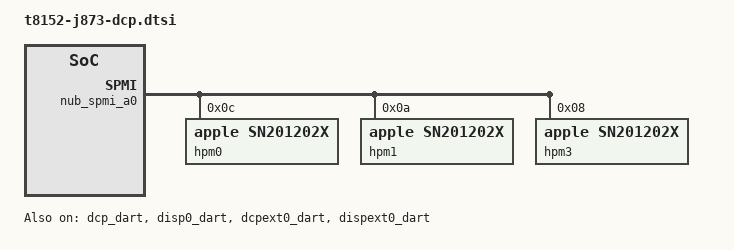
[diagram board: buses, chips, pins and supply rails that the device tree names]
// SPDX-License-Identifier: GPL-2.0+ OR MIT
/*
 * J873g displays: the rear USB-C ports and the HDMI port, driven through
 * the DCP firmware's iBoot interface (apple,t8152-dcp-iboot). The
 * bootloader trains the displays and hands both DCPs over with their RTKit
 * sessions running.
 *
 * Resources are from the 26A434 ADT: dcp (iop,ascwrap-v8, post-office
 * mailbox 5 with alias: 0x316020000 + 2 * 5 * 0x80), dart-dcp (SID 23),
 * dart-disp0 (scanout SID 0), and the atc-phyN PHY windows. The Gen3
 * display DARTs stay locked by iBoot, each with its own live root, so the
 * scanout stream is a child device with its own domain. Linux tables are
 * published into vacant root slots, so the DMA window is the upper half of
 * the 64 GiB vm-base window, above the firmware's and the bootloader's
 * mappings.
 */
#include <dt-bindings/gpio/gpio.h>
#include <dt-bindings/spmi/spmi.h>

&dcp_dart {
	apple,dma-range = <0x108 0x0 0x8 0x0>;
	status = "okay";
};

&disp0_dart {
	apple,dma-range = <0x108 0x0 0x8 0x0>;
	status = "okay";
};

&dcpext0_dart {
	apple,dma-range = <0x108 0x0 0x8 0x0>;
	status = "okay";
};

&dispext0_dart {
	apple,dma-range = <0x108 0x0 0x8 0x0>;
	status = "okay";
};

/ {
	soc {
		/*
		 * ADT /arm-io/nub-spmi-a0 (gen 4): the USB-C PD controllers of
		 * the three rear ports, each of which can carry the USB-C display.
		 */
		nub_spmi_a0: spmi@308908000 {
			compatible = "apple,t8152-spmi", "apple,t8142-spmi";
			reg = <0x3 0x08908000 0x0 0x4000>;
			#address-cells = <2>;
			#size-cells = <0>;

			/* back-middle */
			hpm0: usb-pd@c {
				compatible = "apple,sn201202x";
				reg = <0xc SPMI_USID>;
			};

			/* back-left */
			hpm1: usb-pd@a {
				compatible = "apple,sn201202x";
				reg = <0xa SPMI_USID>;
			};

			/* back-right */
			hpm3: usb-pd@8 {
				compatible = "apple,sn201202x";
				reg = <0x8 SPMI_USID>;
			};
		};

		/*
		 * ADT aop-gpio. Its interrupts are the AOP's, so it has no
		 * interrupt controller here; the HDMI HPD line is polled.
		 */
		pinctrl_aop: pinctrl@310824000 {
			compatible = "apple,t8152-pinctrl", "apple,t8103-pinctrl";
			reg = <0x3 0x10824000 0x0 0x4000>;
			gpio-controller;
			#gpio-cells = <2>;
			gpio-ranges = <&pinctrl_aop 0 0 77>;
			apple,npins = <77>;
		};

		dcp_mbox: mailbox@316020500 {
			compatible = "apple,t8152-ascwrap-v8-mailbox";
			reg = <0x3 0x16020500 0x0 0x80>;
			interrupts = <AIC_IRQ 304 IRQ_TYPE_LEVEL_HIGH>,
				     <AIC_IRQ 264 IRQ_TYPE_LEVEL_HIGH>;
			interrupt-names = "send-empty", "recv-not-empty";
			#mbox-cells = <0>;
		};

		dcp_iboot: display@286e00000 {
			compatible = "apple,t8152-dcp-iboot";
			reg = <0x2 0x86e00000 0x0 0x74000>,
			      <0x3 0x0002005c 0x0 0x4>,
			      <0x3 0x1a760000 0x0 0x4000>,
			      <0x3 0x00700460 0x0 0x4>;
			/* aux: ADT dptx0-aux, aux-ps: PMGR GLOBAL_AUX_CTRL0 */
			reg-names = "coproc", "dp-clock", "aux", "aux-ps";
			#address-cells = <2>;
			#size-cells = <2>;
			ranges;
			mboxes = <&dcp_mbox>;
			iommus = <&dcp_dart 23>;
			/*
			 * Cacheable DMA, as iBoot maps DCP buffers: the firmware
			 * faults on entries with the DART's no-cache bit.
			 */
			dma-coherent;

			/*
			 * The display pipe's own stream: a separate device, so
			 * its domain imports dart-disp0's root, not dart-dcp's.
			 */
			scanout {
				iommus = <&disp0_dart 0>;
				dma-coherent;
			};

			/*
			 * USB-C back-middle: ADT atc-phy0. PS: the ATC's DP_0, DP_1 and
			 * USB_AON power states (+0, +0x20, +0x100), PSD: its common
			 * domain. Tunables before and after the lane crossbar setup.
			 */
			usb-c@403000000 {
				reg = <0x4 0x03000000 0x0 0x84000>,
				      <0x3 0x08290000 0x0 0x104>,
				      <0x3 0x03a13700 0x0 0xc0>;
				reg-names = "atc", "atc-ps", "atc-psd";
				apple,dfp-endpoint = <0>;
				apple,usb-pd = <&hpm0>;
				apple,tunable-pre =
					/* ACIOPHY_CMN_DFLT */
					<0x00800 0x00fc0000 0x00fc0000>,
					<0x0084c 0x000ff800 0x000ff800>,
					<0x0085c 0x000000ff 0x00000080>,
					<0x00860 0x007fffff 0x0052bca4>,
					<0x00864 0x02c00000 0x00800000>,
					/* CIOPLL_CORE_DFLT */
					<0x01614 0x0003ffc0 0x0001e5c0>,
					<0x01640 0x00000007 0x00000003>,
					<0x01668 0x00000ffc 0x000005f0>;
				apple,tunable-post =
					/* ATC_FABRIC */
					<0x6c004 0x003f003f 0x00200020>,
					<0x6c00c 0x000000f1 0x000000a1>,
					<0x6c010 0x0000801f 0x00000004>,
					<0x6c018 0x003f003f 0x00200020>,
					<0x6c020 0x000000f1 0x000000a1>,
					<0x6c024 0x0000801f 0x00000004>,
					<0x6c02c 0x007f007f 0x00410041>,
					<0x6c034 0x000000f1 0x00000071>,
					<0x6c038 0x0000801f 0x00000004>,
					<0x6c040 0x0000001f 0x00000010>,
					<0x6c048 0x0000801f 0x00000004>,
					<0x6c050 0x007f007f 0x00450045>,
					<0x6c058 0x000000f1 0x00000051>,
					<0x6c05c 0x0000801f 0x00000004>,
					<0x6c064 0x0000003f 0x00000020>,
					<0x6c06c 0x0000801f 0x00000004>,
					<0x6c074 0x00000001 0x00000001>,
					<0x6c078 0x0000801f 0x00000004>,
					<0x6c080 0x001f001f 0x00100010>,
					<0x6c084 0x000000f1 0x00000011>,
					<0x6c088 0x00000001 0x00000001>,
					<0x6c08c 0x00000001 0x00000001>,
					<0x6c090 0x0000801f 0x00000004>,
					<0x6c098 0x001f001f 0x00100010>,
					<0x6c09c 0x000000f1 0x00000011>,
					<0x6c0a0 0x0000801f 0x00000004>,
					<0x6c0a8 0x000000ff 0x000000a0>,
					<0x6c0ac 0x0000801f 0x00000004>,
					<0x6c0b4 0x0000003f 0x00000020>,
					<0x6c0bc 0x0000801f 0x00000004>,
					<0x6c0c4 0x0000003f 0x00000020>,
					<0x6c0cc 0x0000801f 0x00000004>,
					<0x6c0d4 0x0000000f 0x00000008>,
					<0x6c0d8 0x0000801f 0x00000004>,
					<0x6c0e0 0x001f001f 0x00180018>,
					<0x6c0e4 0x0000801f 0x00000004>,
					<0x6c0ec 0x001f001f 0x00180018>,
					<0x6c0f0 0x0000801f 0x00000004>,
					<0x6c0f8 0x001f001f 0x00180018>,
					<0x6c0fc 0x0000801f 0x00000004>,
					<0x6c104 0x001f001f 0x00180018>,
					<0x6c108 0x0000801f 0x00000004>,
					<0x6c110 0x00000001 0x00000001>,
					<0x6c114 0x0000801f 0x00000004>,
					<0x6c11c 0x0000801f 0x00000004>,
					<0x6c124 0x0000801f 0x00000004>,
					<0x6c12c 0x0000801f 0x00000004>,
					<0x6c134 0x0000801f 0x00000004>,
					<0x6c13c 0xffffffff 0x01010101>,
					<0x6c140 0x0000801f 0x00000004>,
					<0x6c148 0x0000801f 0x00000004>,
					<0x6c150 0xffffffff 0x01010101>,
					<0x6c154 0x0000ffff 0x00000101>,
					<0x6c158 0x0000801f 0x00000004>,
					<0x6c160 0x0000801f 0x00000004>,
					<0x6c168 0x0000801f 0x00000004>,
					<0x6c170 0x0000801f 0x00000004>,
					<0x6c178 0x0000801f 0x00000004>,
					<0x6c180 0xffffffff 0x01010101>,
					<0x6c184 0x0000801f 0x00000004>,
					<0x6c18c 0x0000801f 0x00000004>,
					<0x6c194 0x0000801f 0x00000004>,
					/* DPPLL_CORE_DFLT */
					<0x01040 0x0000000c 0x00000008>,
					<0x01060 0x0001c000 0x0000c000>,
					<0x01098 0x00000f00 0x00000800>,
					<0x0109c 0x000fe000 0x000fe000>,
					<0x01108 0x07c00000 0x04000000>,
					<0x0110c 0x0000007c 0x00000010>,
					/* DPPLL_TOP_DFLT */
					<0x00e8c 0x0000007f 0x0000003c>,
					<0x00e9c 0x0000007f 0x00000032>,
					<0x00eac 0x0000007f 0x00000032>,
					<0x00ebc 0x0000007f 0x0000005a>,
					/* ASDC_AUX_SHM_DFLT */
					<0x02308 0x000000fc 0x00000084>;
			};

			/*
			 * USB-C back-left: ADT atc-phy1. PS: the ATC's DP_0, DP_1 and
			 * USB_AON power states (+0, +0x20, +0x100), PSD: its common
			 * domain. Tunables before and after the lane crossbar setup.
			 */
			usb-c@40b000000 {
				reg = <0x4 0x0b000000 0x0 0x84000>,
				      <0x3 0x08290040 0x0 0x104>,
				      <0x3 0x03a13800 0x0 0xc0>;
				reg-names = "atc", "atc-ps", "atc-psd";
				apple,dfp-endpoint = <1>;
				apple,usb-pd = <&hpm1>;
				apple,tunable-pre =
					/* ACIOPHY_CMN_DFLT */
					<0x00800 0x00fc0000 0x00fc0000>,
					<0x0084c 0x000ff800 0x000ff800>,
					<0x0085c 0x000000ff 0x00000080>,
					<0x00860 0x007fffff 0x0052bc26>,
					<0x00864 0x02c00000 0x00800000>,
					/* CIOPLL_CORE_DFLT */
					<0x01614 0x0003ffc0 0x0001e5c0>,
					<0x01640 0x00000007 0x00000003>,
					<0x01668 0x00000ffc 0x000005f0>;
				apple,tunable-post =
					/* ATC_FABRIC */
					<0x6c004 0x003f003f 0x00200020>,
					<0x6c00c 0x000000f1 0x000000a1>,
					<0x6c010 0x0000801f 0x00000004>,
					<0x6c018 0x003f003f 0x00200020>,
					<0x6c020 0x000000f1 0x000000a1>,
					<0x6c024 0x0000801f 0x00000004>,
					<0x6c02c 0x007f007f 0x00410041>,
					<0x6c034 0x000000f1 0x00000071>,
					<0x6c038 0x0000801f 0x00000004>,
					<0x6c040 0x0000001f 0x00000010>,
					<0x6c048 0x0000801f 0x00000004>,
					<0x6c050 0x007f007f 0x00450045>,
					<0x6c058 0x000000f1 0x00000051>,
					<0x6c05c 0x0000801f 0x00000004>,
					<0x6c064 0x0000003f 0x00000020>,
					<0x6c06c 0x0000801f 0x00000004>,
					<0x6c074 0x00000001 0x00000001>,
					<0x6c078 0x0000801f 0x00000004>,
					<0x6c080 0x001f001f 0x00100010>,
					<0x6c084 0x000000f1 0x00000011>,
					<0x6c088 0x00000001 0x00000001>,
					<0x6c08c 0x00000001 0x00000001>,
					<0x6c090 0x0000801f 0x00000004>,
					<0x6c098 0x001f001f 0x00100010>,
					<0x6c09c 0x000000f1 0x00000011>,
					<0x6c0a0 0x0000801f 0x00000004>,
					<0x6c0a8 0x000000ff 0x000000a0>,
					<0x6c0ac 0x0000801f 0x00000004>,
					<0x6c0b4 0x0000003f 0x00000020>,
					<0x6c0bc 0x0000801f 0x00000004>,
					<0x6c0c4 0x0000003f 0x00000020>,
					<0x6c0cc 0x0000801f 0x00000004>,
					<0x6c0d4 0x0000000f 0x00000008>,
					<0x6c0d8 0x0000801f 0x00000004>,
					<0x6c0e0 0x001f001f 0x00180018>,
					<0x6c0e4 0x0000801f 0x00000004>,
					<0x6c0ec 0x001f001f 0x00180018>,
					<0x6c0f0 0x0000801f 0x00000004>,
					<0x6c0f8 0x001f001f 0x00180018>,
					<0x6c0fc 0x0000801f 0x00000004>,
					<0x6c104 0x001f001f 0x00180018>,
					<0x6c108 0x0000801f 0x00000004>,
					<0x6c110 0x00000001 0x00000001>,
					<0x6c114 0x0000801f 0x00000004>,
					<0x6c11c 0x0000801f 0x00000004>,
					<0x6c124 0x0000801f 0x00000004>,
					<0x6c12c 0x0000801f 0x00000004>,
					<0x6c134 0x0000801f 0x00000004>,
					<0x6c13c 0xffffffff 0x01010101>,
					<0x6c140 0x0000801f 0x00000004>,
					<0x6c148 0x0000801f 0x00000004>,
					<0x6c150 0xffffffff 0x01010101>,
					<0x6c154 0x0000ffff 0x00000101>,
					<0x6c158 0x0000801f 0x00000004>,
					<0x6c160 0x0000801f 0x00000004>,
					<0x6c168 0x0000801f 0x00000004>,
					<0x6c170 0x0000801f 0x00000004>,
					<0x6c178 0x0000801f 0x00000004>,
					<0x6c180 0xffffffff 0x01010101>,
					<0x6c184 0x0000801f 0x00000004>,
					<0x6c18c 0x0000801f 0x00000004>,
					<0x6c194 0x0000801f 0x00000004>,
					/* DPPLL_CORE_DFLT */
					<0x01040 0x0000000c 0x00000008>,
					<0x01060 0x0001c000 0x0000c000>,
					<0x01098 0x00000f00 0x00000800>,
					<0x0109c 0x000fe000 0x000fe000>,
					<0x01108 0x07c00000 0x04000000>,
					<0x0110c 0x0000007c 0x00000010>,
					/* DPPLL_TOP_DFLT */
					<0x00e8c 0x0000007f 0x0000003c>,
					<0x00e9c 0x0000007f 0x00000032>,
					<0x00eac 0x0000007f 0x00000032>,
					<0x00ebc 0x0000007f 0x0000005a>,
					/* ASDC_AUX_SHM_DFLT */
					<0x02308 0x000000fc 0x00000084>;
			};

			/*
			 * USB-C back-right: ADT atc-phy3. PS: the ATC's DP_0, DP_1 and
			 * USB_AON power states (+0, +0x20, +0x100), PSD: its common
			 * domain. Tunables before and after the lane crossbar setup.
			 */
			usb-c@413000000 {
				reg = <0x4 0x13000000 0x0 0x84000>,
				      <0x3 0x082900c0 0x0 0x104>,
				      <0x3 0x03a13a00 0x0 0xc0>;
				reg-names = "atc", "atc-ps", "atc-psd";
				apple,dfp-endpoint = <3>;
				apple,usb-pd = <&hpm3>;
				apple,tunable-pre =
					/* ACIOPHY_CMN_DFLT */
					<0x00800 0x00fc0000 0x00fc0000>,
					<0x0084c 0x000ff800 0x000ff800>,
					<0x0085c 0x000000ff 0x00000080>,
					<0x00860 0x007fffff 0x0052bc26>,
					<0x00864 0x02c00000 0x00800000>,
					/* CIOPLL_CORE_DFLT */
					<0x01614 0x0003ffc0 0x0001e5c0>,
					<0x01640 0x00000007 0x00000003>,
					<0x01668 0x00000ffc 0x000005f0>;
				apple,tunable-post =
					/* ATC_FABRIC */
					<0x6c004 0x003f003f 0x00200020>,
					<0x6c00c 0x000000f1 0x000000a1>,
					<0x6c010 0x0000801f 0x00000004>,
					<0x6c018 0x003f003f 0x00200020>,
					<0x6c020 0x000000f1 0x000000a1>,
					<0x6c024 0x0000801f 0x00000004>,
					<0x6c02c 0x007f007f 0x00410041>,
					<0x6c034 0x000000f1 0x00000071>,
					<0x6c038 0x0000801f 0x00000004>,
					<0x6c040 0x0000001f 0x00000010>,
					<0x6c048 0x0000801f 0x00000004>,
					<0x6c050 0x007f007f 0x00450045>,
					<0x6c058 0x000000f1 0x00000051>,
					<0x6c05c 0x0000801f 0x00000004>,
					<0x6c064 0x0000003f 0x00000020>,
					<0x6c06c 0x0000801f 0x00000004>,
					<0x6c074 0x00000001 0x00000001>,
					<0x6c078 0x0000801f 0x00000004>,
					<0x6c080 0x001f001f 0x00100010>,
					<0x6c084 0x000000f1 0x00000011>,
					<0x6c088 0x00000001 0x00000001>,
					<0x6c08c 0x00000001 0x00000001>,
					<0x6c090 0x0000801f 0x00000004>,
					<0x6c098 0x001f001f 0x00100010>,
					<0x6c09c 0x000000f1 0x00000011>,
					<0x6c0a0 0x0000801f 0x00000004>,
					<0x6c0a8 0x000000ff 0x000000a0>,
					<0x6c0ac 0x0000801f 0x00000004>,
					<0x6c0b4 0x0000003f 0x00000020>,
					<0x6c0bc 0x0000801f 0x00000004>,
					<0x6c0c4 0x0000003f 0x00000020>,
					<0x6c0cc 0x0000801f 0x00000004>,
					<0x6c0d4 0x0000000f 0x00000008>,
					<0x6c0d8 0x0000801f 0x00000004>,
					<0x6c0e0 0x001f001f 0x00180018>,
					<0x6c0e4 0x0000801f 0x00000004>,
					<0x6c0ec 0x001f001f 0x00180018>,
					<0x6c0f0 0x0000801f 0x00000004>,
					<0x6c0f8 0x001f001f 0x00180018>,
					<0x6c0fc 0x0000801f 0x00000004>,
					<0x6c104 0x001f001f 0x00180018>,
					<0x6c108 0x0000801f 0x00000004>,
					<0x6c110 0x00000001 0x00000001>,
					<0x6c114 0x0000801f 0x00000004>,
					<0x6c11c 0x0000801f 0x00000004>,
					<0x6c124 0x0000801f 0x00000004>,
					<0x6c12c 0x0000801f 0x00000004>,
					<0x6c134 0x0000801f 0x00000004>,
					<0x6c13c 0xffffffff 0x01010101>,
					<0x6c140 0x0000801f 0x00000004>,
					<0x6c148 0x0000801f 0x00000004>,
					<0x6c150 0xffffffff 0x01010101>,
					<0x6c154 0x0000ffff 0x00000101>,
					<0x6c158 0x0000801f 0x00000004>,
					<0x6c160 0x0000801f 0x00000004>,
					<0x6c168 0x0000801f 0x00000004>,
					<0x6c170 0x0000801f 0x00000004>,
					<0x6c178 0x0000801f 0x00000004>,
					<0x6c180 0xffffffff 0x01010101>,
					<0x6c184 0x0000801f 0x00000004>,
					<0x6c18c 0x0000801f 0x00000004>,
					<0x6c194 0x0000801f 0x00000004>,
					/* DPPLL_CORE_DFLT */
					<0x01040 0x0000000c 0x00000008>,
					<0x01060 0x0001c000 0x0000c000>,
					<0x01098 0x00000f00 0x00000800>,
					<0x0109c 0x000fe000 0x000fe000>,
					<0x01108 0x07c00000 0x04000000>,
					<0x0110c 0x0000007c 0x00000010>,
					/* DPPLL_TOP_DFLT */
					<0x00e8c 0x0000007f 0x0000003c>,
					<0x00e9c 0x0000007f 0x00000032>,
					<0x00eac 0x0000007f 0x00000032>,
					<0x00ebc 0x0000007f 0x0000005a>,
					/* ASDC_AUX_SHM_DFLT */
					<0x02308 0x000000fc 0x00000084>;
			};
		};

		/*
		 * HDMI: DCPEXT0 (post-office mailbox 6) drives the dedicated
		 * dptx-phy through the PS190 converter. ADT dcpext0,
		 * dart-dcpext0 and dart-dispext0.
		 */
		dcpext_mbox: mailbox@316020600 {
			compatible = "apple,t8152-ascwrap-v8-mailbox";
			reg = <0x3 0x16020600 0x0 0x80>;
			interrupts = <AIC_IRQ 305 IRQ_TYPE_LEVEL_HIGH>,
				     <AIC_IRQ 265 IRQ_TYPE_LEVEL_HIGH>;
			interrupt-names = "send-empty", "recv-not-empty";
			#mbox-cells = <0>;
		};

		dcpext_iboot: display@32ae00000 {
			compatible = "apple,t8152-dcp-iboot";
			reg = <0x3 0x2ae00000 0x0 0x74000>,
			      <0x3 0x1a740000 0x0 0x10000>,
			      <0x3 0x1a700000 0x0 0x4000>,
			      <0x3 0x1a764000 0x0 0x4000>,
			      <0x3 0x00700480 0x0 0x4>,
			      <0x3 0x007016c0 0x0 0x4>,
			      <0x3 0x00700e00 0x0 0x4>;
			/* aux: ADT dptx1-aux, aux-ps: PMGR GLOBAL_AUX_CTRL1 */
			/* Read-only PMGR DPTX_PHY and DISPEXT0_CPU admission checks. */
			reg-names = "coproc", "phy-core", "phy-apb", "aux", "aux-ps",
				    "phy-ps", "coproc-ps";
			mboxes = <&dcpext_mbox>;
			iommus = <&dcpext0_dart 23>;
			dma-coherent;
			apple,hdmi;
			/* ADT dp2hdmi-gpio0 function-hdmi_hpd */
			hpd-gpios = <&pinctrl_aop 41 GPIO_ACTIVE_HIGH>;

			scanout {
				iommus = <&dispext0_dart 0>;
				dma-coherent;
			};
		};
	};
};
